# iostr910f register map
Registers are 32-bit, access not given, no defined reset value unless marked. A register's access mark holds for its fields unless they carry their own. Addresses are absolute; registers are grouped by the start of their names; [hi:lo] are bit positions; {n}, {i} and the like mark numbered series; 'fields as' and 'values as' point back to an identical list.

## GPIO4
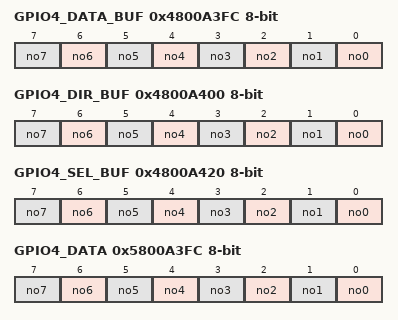
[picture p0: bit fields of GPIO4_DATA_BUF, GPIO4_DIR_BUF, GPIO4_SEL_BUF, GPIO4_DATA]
0x4800A3FC GPIO4_DATA_BUF 8-bit
  [n] no{n} (n=0..7)
0x4800A400 GPIO4_DIR_BUF 8-bit
  [n] no{n} (n=0..7)
0x4800A420 GPIO4_SEL_BUF 8-bit
  [n] no{n} (n=0..7)
0x5800A3FC GPIO4_DATA 8-bit
  [n] no{n} (n=0..7)
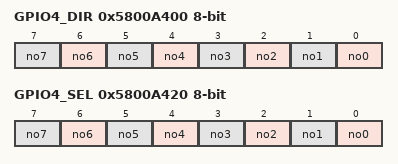
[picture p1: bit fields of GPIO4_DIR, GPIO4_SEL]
0x5800A400 GPIO4_DIR 8-bit
  [n] no{n} (n=0..7)
0x5800A420 GPIO4_SEL 8-bit
  [n] no{n} (n=0..7)

## GPIO5
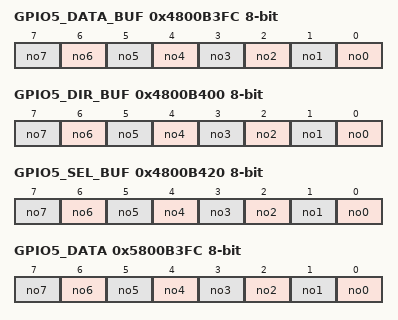
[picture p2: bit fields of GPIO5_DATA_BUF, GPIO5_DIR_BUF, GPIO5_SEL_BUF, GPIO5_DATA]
0x4800B3FC GPIO5_DATA_BUF 8-bit
  [n] no{n} (n=0..7)
0x4800B400 GPIO5_DIR_BUF 8-bit
  [n] no{n} (n=0..7)
0x4800B420 GPIO5_SEL_BUF 8-bit
  [n] no{n} (n=0..7)
0x5800B3FC GPIO5_DATA 8-bit
  [n] no{n} (n=0..7)
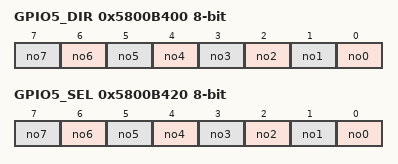
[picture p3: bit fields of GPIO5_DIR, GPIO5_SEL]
0x5800B400 GPIO5_DIR 8-bit
  [n] no{n} (n=0..7)
0x5800B420 GPIO5_SEL 8-bit
  [n] no{n} (n=0..7)

## GPIO6
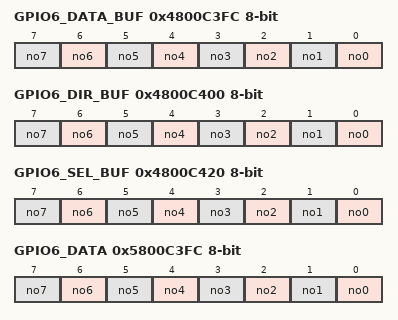
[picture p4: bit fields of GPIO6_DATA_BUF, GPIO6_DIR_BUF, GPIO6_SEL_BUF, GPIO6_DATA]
0x4800C3FC GPIO6_DATA_BUF 8-bit
  [n] no{n} (n=0..7)
0x4800C400 GPIO6_DIR_BUF 8-bit
  [n] no{n} (n=0..7)
0x4800C420 GPIO6_SEL_BUF 8-bit
  [n] no{n} (n=0..7)
0x5800C3FC GPIO6_DATA 8-bit
  [n] no{n} (n=0..7)
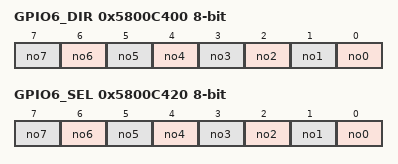
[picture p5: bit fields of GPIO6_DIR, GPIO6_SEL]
0x5800C400 GPIO6_DIR 8-bit
  [n] no{n} (n=0..7)
0x5800C420 GPIO6_SEL 8-bit
  [n] no{n} (n=0..7)

## GPIO7
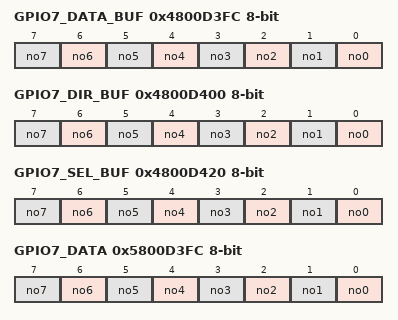
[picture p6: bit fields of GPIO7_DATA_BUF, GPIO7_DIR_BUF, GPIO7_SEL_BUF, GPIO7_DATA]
0x4800D3FC GPIO7_DATA_BUF 8-bit
  [n] no{n} (n=0..7)
0x4800D400 GPIO7_DIR_BUF 8-bit
  [n] no{n} (n=0..7)
0x4800D420 GPIO7_SEL_BUF 8-bit
  [n] no{n} (n=0..7)
0x5800D3FC GPIO7_DATA 8-bit
  [n] no{n} (n=0..7)
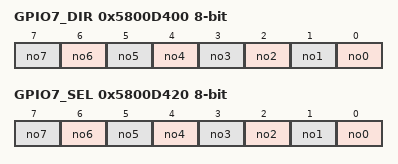
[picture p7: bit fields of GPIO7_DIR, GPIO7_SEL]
0x5800D400 GPIO7_DIR 8-bit
  [n] no{n} (n=0..7)
0x5800D420 GPIO7_SEL 8-bit
  [n] no{n} (n=0..7)

## GPIO8
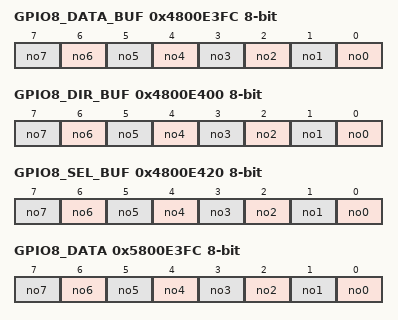
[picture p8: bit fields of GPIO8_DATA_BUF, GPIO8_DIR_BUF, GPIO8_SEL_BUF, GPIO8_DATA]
0x4800E3FC GPIO8_DATA_BUF 8-bit
  [n] no{n} (n=0..7)
0x4800E400 GPIO8_DIR_BUF 8-bit
  [n] no{n} (n=0..7)
0x4800E420 GPIO8_SEL_BUF 8-bit
  [n] no{n} (n=0..7)
0x5800E3FC GPIO8_DATA 8-bit
  [n] no{n} (n=0..7)
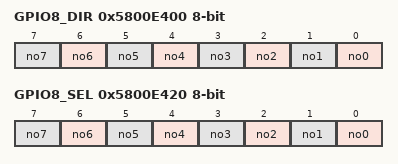
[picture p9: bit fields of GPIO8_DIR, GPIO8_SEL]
0x5800E400 GPIO8_DIR 8-bit
  [n] no{n} (n=0..7)
0x5800E420 GPIO8_SEL 8-bit
  [n] no{n} (n=0..7)

## GPIO9
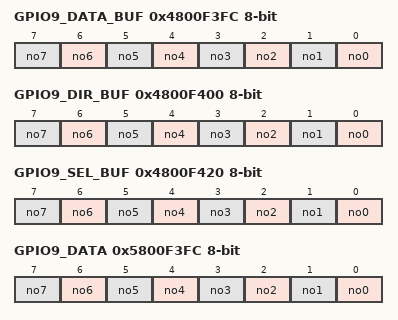
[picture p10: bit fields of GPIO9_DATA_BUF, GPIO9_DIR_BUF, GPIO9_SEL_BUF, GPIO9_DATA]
0x4800F3FC GPIO9_DATA_BUF 8-bit
  [n] no{n} (n=0..7)
0x4800F400 GPIO9_DIR_BUF 8-bit
  [n] no{n} (n=0..7)
0x4800F420 GPIO9_SEL_BUF 8-bit
  [n] no{n} (n=0..7)
0x5800F3FC GPIO9_DATA 8-bit
  [n] no{n} (n=0..7)
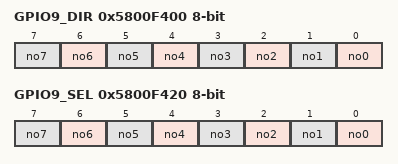
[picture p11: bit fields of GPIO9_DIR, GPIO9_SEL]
0x5800F400 GPIO9_DIR 8-bit
  [n] no{n} (n=0..7)
0x5800F420 GPIO9_SEL 8-bit
  [n] no{n} (n=0..7)

## VIC0
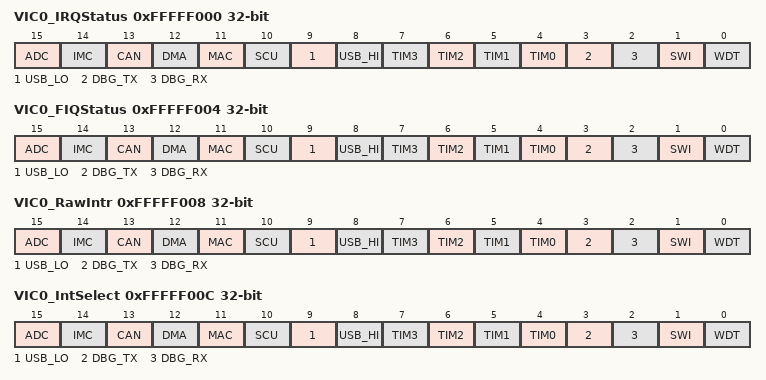
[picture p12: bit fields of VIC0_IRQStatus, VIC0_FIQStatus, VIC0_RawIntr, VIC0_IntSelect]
0xFFFFF000 VIC0_IRQStatus
  [15] ADC, [14] IMC, [13] CAN, [12] DMA, [11] MAC, [10] SCU, [9] USB_LO, [8] USB_HI, [n+4] TIM{n} (n=0..3), [3] DBG_TX, [2] DBG_RX, [1] SWI, [0] WDT
0xFFFFF004 VIC0_FIQStatus
  fields as VIC0_IRQStatus
0xFFFFF008 VIC0_RawIntr
  fields as VIC0_IRQStatus
0xFFFFF00C VIC0_IntSelect
  fields as VIC0_IRQStatus
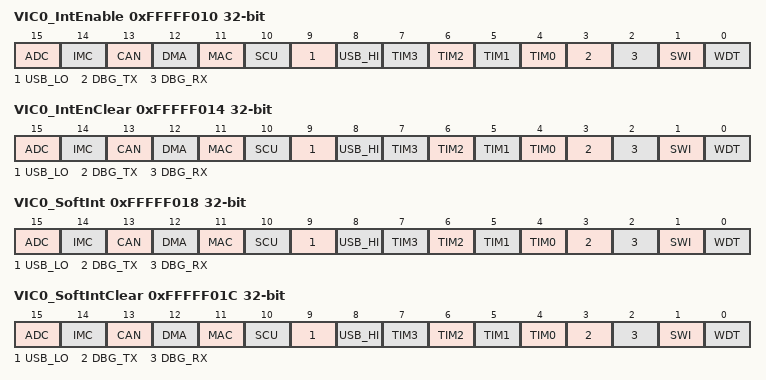
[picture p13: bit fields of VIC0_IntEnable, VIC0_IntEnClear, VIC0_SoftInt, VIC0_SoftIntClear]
0xFFFFF010 VIC0_IntEnable
  fields as VIC0_IRQStatus
0xFFFFF014 VIC0_IntEnClear
  fields as VIC0_IRQStatus
0xFFFFF018 VIC0_SoftInt
  fields as VIC0_IRQStatus
0xFFFFF01C VIC0_SoftIntClear
  fields as VIC0_IRQStatus
0xFFFFF020 VIC0_Protection
  [0] PROT
0xFFFFF030 VIC0_CurrVectAddr
0xFFFFF034 VIC0_DefVectAddr
{0xFFFFF100+4i} VIC0_VectAddr{i} (i=0..15)
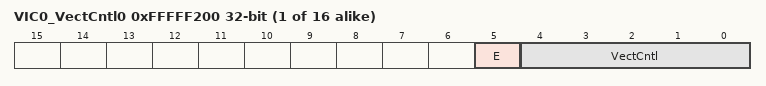
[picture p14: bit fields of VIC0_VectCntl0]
{0xFFFFF200+4i} VIC0_VectCntl{i} (i=0..15)
  [5] E, [4:0] VectCntl

## VIC1
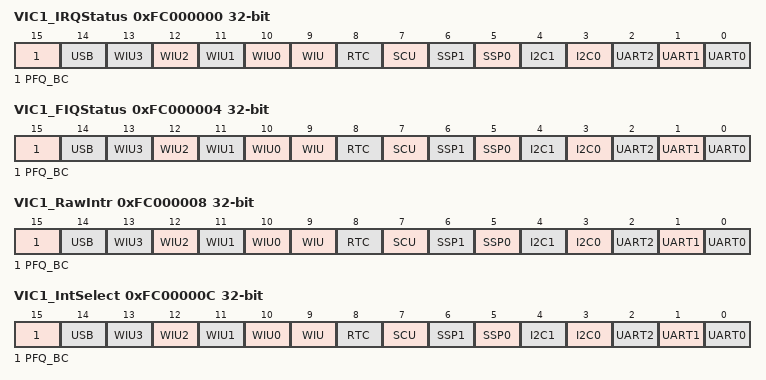
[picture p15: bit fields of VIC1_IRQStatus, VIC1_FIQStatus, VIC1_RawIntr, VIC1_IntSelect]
0xFC000000 VIC1_IRQStatus
  [15] PFQ_BC, [14] USB, [n+10] WIU{n} (n=0..3), [9] WIU, [8] RTC, [7] SCU, [6] SSP1, [5] SSP0, [4] I2C1, [3] I2C0, [2] UART2, [1] UART1, [0] UART0
0xFC000004 VIC1_FIQStatus
  fields as VIC1_IRQStatus
0xFC000008 VIC1_RawIntr
  fields as VIC1_IRQStatus
0xFC00000C VIC1_IntSelect
  fields as VIC1_IRQStatus
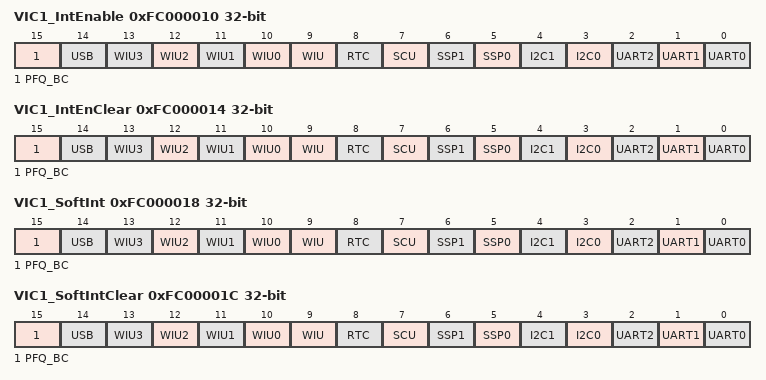
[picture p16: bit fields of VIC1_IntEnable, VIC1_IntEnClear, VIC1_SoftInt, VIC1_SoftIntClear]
0xFC000010 VIC1_IntEnable
  fields as VIC1_IRQStatus
0xFC000014 VIC1_IntEnClear
  fields as VIC1_IRQStatus
0xFC000018 VIC1_SoftInt
  fields as VIC1_IRQStatus
0xFC00001C VIC1_SoftIntClear
  fields as VIC1_IRQStatus
0xFC000020 VIC1_Protection
  [0] PROT
0xFC000030 VIC1_CurrVectAddr
0xFC000034 VIC1_DefVectAddr
{0xFC000100+4i} VIC1_VectAddr{i} (i=0..15)
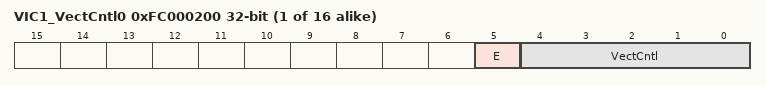
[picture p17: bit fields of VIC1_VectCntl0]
{0xFC000200+4i} VIC1_VectCntl{i} (i=0..15)
  [5] E, [4:0] VectCntl

## WIU
0x48001000 WIU_CTRL_BUF
  [1] INT_EN, [0] WKUP_INT
0x48001004 WIU_MR_BUF
  [n] WUM{n} (n=2..31)
0x48001008 WIU_TR_BUF
  [n] WUT{n} (n=2..31)
0x4800100C WIU_PR_BUF
  [n] WUP{n} (n=2..31)
0x48001010 WIU_INTR_BUF
  [n] WUINTR{n} (n=2..31)
0x58001000 WIU_CTRL
  [1] INT_EN, [0] WKUP_INT
0x58001004 WIU_MR
  [n] WUM{n} (n=2..31)
0x58001008 WIU_TR
  [n] WUT{n} (n=2..31)
0x5800100C WIU_PR
  [n] WUP{n} (n=2..31)
0x58001010 WIU_INTR
  [n] WUINTR{n} (n=2..31)
